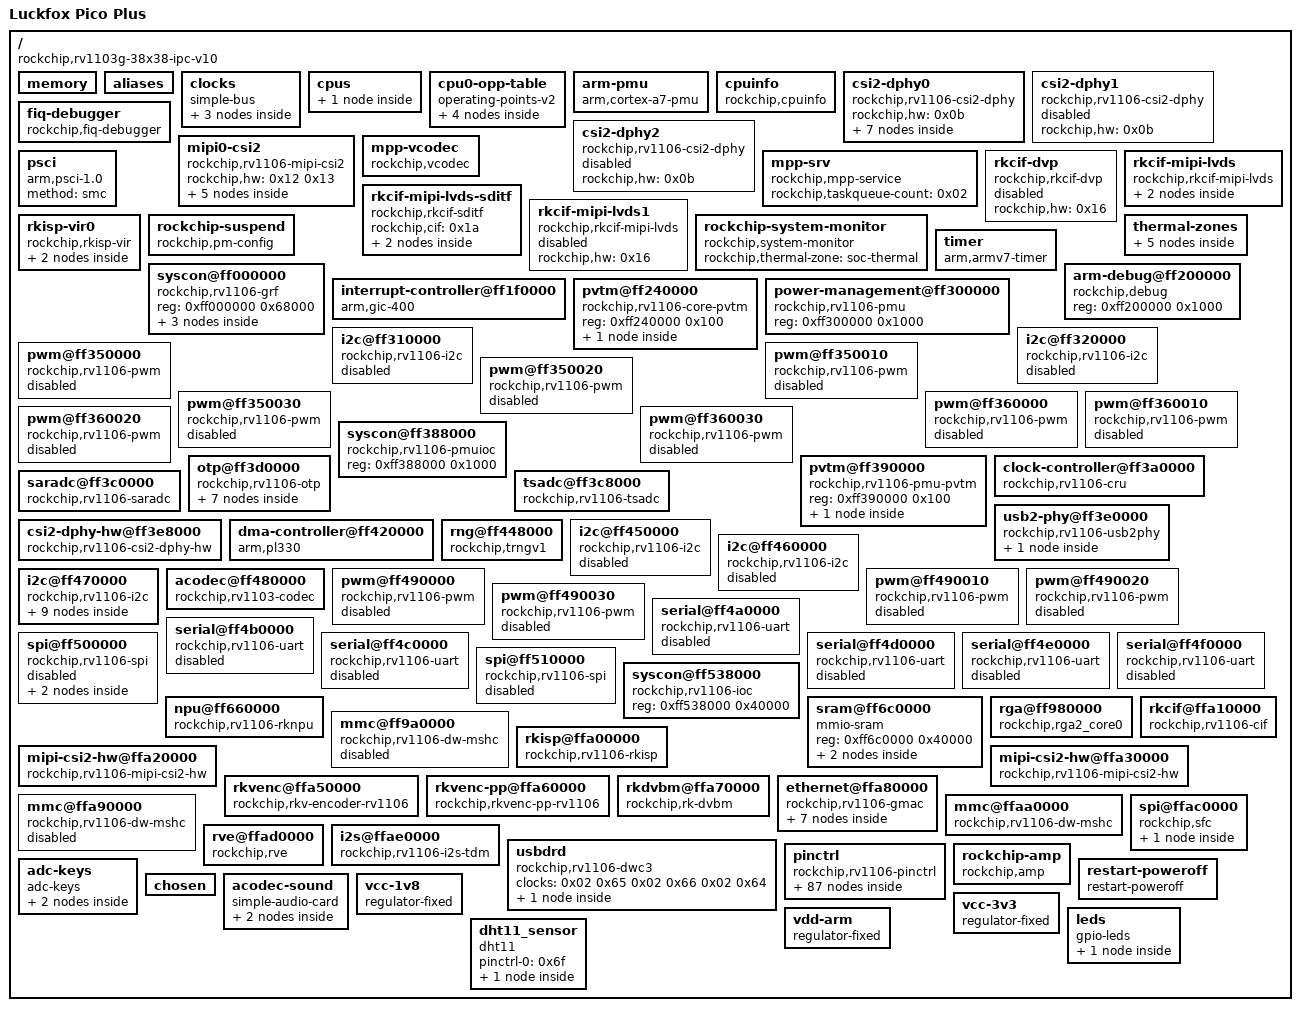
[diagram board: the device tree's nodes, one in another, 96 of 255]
/dts-v1/;

/memreserve/	0x0000000000c00000 0x0000000000009000;
/ {
	serial-number = "6f0e92eba599e63";
	#address-cells = <0x01>;
	#size-cells = <0x01>;
	compatible = "rockchip,rv1103g-38x38-ipc-v10", "rockchip,rv1103";
	interrupt-parent = <0x01>;
	model = "Luckfox Pico Plus";

	memory {
		reg = <0x00 0x4000000 0x00 0x00 0x00 0x00 0x00 0x00 0x00 0x00 0x00 0x00 0x00 0x00 0x00 0x00 0x00 0x00 0x00 0x00 0x00 0x00 0x00 0x00>;
		device_type = "memory";
	};

	aliases {
		csi2dphy0 = "/csi2-dphy0";
		csi2dphy1 = "/csi2-dphy1";
		csi2dphy2 = "/csi2-dphy2";
		ethernet0 = "/ethernet@ffa80000";
		gpio0 = "/pinctrl/gpio@ff380000";
		gpio1 = "/pinctrl/gpio@ff530000";
		gpio3 = "/pinctrl/gpio@ff550000";
		gpio4 = "/pinctrl/gpio@ff560000";
		i2c0 = "/i2c@ff310000";
		i2c1 = "/i2c@ff320000";
		i2c2 = "/i2c@ff450000";
		i2c3 = "/i2c@ff460000";
		i2c4 = "/i2c@ff470000";
		mmc0 = "/mmc@ffa90000";
		mmc1 = "/mmc@ffaa0000";
		mmc2 = "/mmc@ff9a0000";
		pwm0 = "/pwm@ff350000";
		pwm1 = "/pwm@ff350010";
		pwm2 = "/pwm@ff350020";
		pwm3 = "/pwm@ff350030";
		pwm4 = "/pwm@ff360000";
		pwm5 = "/pwm@ff360010";
		pwm6 = "/pwm@ff360020";
		pwm7 = "/pwm@ff360030";
		pwm8 = "/pwm@ff490000";
		pwm9 = "/pwm@ff490010";
		pwm10 = "/pwm@ff490020";
		pwm11 = "/pwm@ff490030";
		rkcif_mipi_lvds0 = "/rkcif-mipi-lvds";
		rkcif_mipi_lvds1 = "/rkcif-mipi-lvds1";
		serial0 = "/serial@ff4a0000";
		serial1 = "/serial@ff4b0000";
		serial2 = "/serial@ff4c0000";
		serial3 = "/serial@ff4d0000";
		serial4 = "/serial@ff4e0000";
		serial5 = "/serial@ff4f0000";
		spi0 = "/spi@ff500000";
		spi1 = "/spi@ff510000";
		spi2 = "/spi@ffac0000";
	};

	clocks {
		compatible = "simple-bus";

		pvtpll-0 {
			compatible = "fixed-clock";
			clock-frequency = <0x18701a80>;
			clock-output-names = "clk_pvtpll_0";
			#clock-cells = <0x00>;
		};

		pvtpll-1 {
			compatible = "fixed-clock";
			clock-frequency = <0x1908b100>;
			clock-output-names = "clk_pvtpll_1";
			#clock-cells = <0x00>;
		};

		oscillator {
			compatible = "fixed-clock";
			clock-frequency = <0x16e3600>;
			clock-output-names = "xin24m";
			#clock-cells = <0x00>;
		};
	};

	cpus {
		#address-cells = <0x01>;
		#size-cells = <0x00>;

		cpu@0 {
			device_type = "cpu";
			compatible = "arm,cortex-a7";
			reg = <0x00>;
			clocks = <0x02 0x05>;
			operating-points-v2 = <0x03>;
			cpu-supply = <0x04>;
			phandle = <0x07>;
		};
	};

	cpu0-opp-table {
		compatible = "operating-points-v2";
		opp-shared;
		nvmem-cells = <0x05>;
		nvmem-cell-names = "leakage";
		rockchip,pvtpll-avg-offset = <0x4001c>;
		rockchip,pvtpll-min-rate = <0x10d880>;
		rockchip,pvtpll-volt-step = <0x30d4>;
		rockchip,grf = <0x06>;
		rockchip,temp-hysteresis = <0x1388>;
		rockchip,low-temp = <0x2710>;
		rockchip,low-temp-min-volt = <0xdbba0>;
		phandle = <0x03>;

		opp-408000000 {
			opp-hz = <0x00 0x18519600>;
			opp-microvolt = <0xcf850 0xcf850 0xf4240>;
			clock-latency-ns = <0x9c40>;
		};

		opp-600000000 {
			opp-hz = <0x00 0x23c34600>;
			opp-microvolt = <0xcf850 0xcf850 0xf4240>;
			clock-latency-ns = <0x9c40>;
		};

		opp-816000000 {
			opp-hz = <0x00 0x30a32c00>;
			opp-microvolt = <0xcf850 0xcf850 0xf4240>;
			clock-latency-ns = <0x9c40>;
			opp-suspend;
		};

		opp-1104000000 {
			opp-hz = <0x00 0x41cdb400>;
			opp-microvolt = <0xcf850 0xcf850 0xf4240>;
			clock-latency-ns = <0x9c40>;
		};
	};

	arm-pmu {
		compatible = "arm,cortex-a7-pmu";
		interrupts = <0x00 0x7e 0x04>;
		interrupt-affinity = <0x07>;
	};

	cpuinfo {
		compatible = "rockchip,cpuinfo";
		nvmem-cells = <0x08 0x09 0x0a>;
		nvmem-cell-names = "id", "cpu-version", "cpu-code";
	};

	csi2-dphy0 {
		compatible = "rockchip,rv1106-csi2-dphy";
		rockchip,hw = <0x0b>;
		status = "okay";

		ports {
			#address-cells = <0x01>;
			#size-cells = <0x00>;

			port@0 {
				reg = <0x00>;
				#address-cells = <0x01>;
				#size-cells = <0x00>;

				endpoint@0 {
					reg = <0x00>;
					remote-endpoint = <0x0c>;
					data-lanes = <0x01 0x02>;
					phandle = <0x33>;
				};

				endpoint@1 {
					reg = <0x01>;
					remote-endpoint = <0x0d>;
					data-lanes = <0x01 0x02>;
					phandle = <0x34>;
				};

				endpoint@2 {
					reg = <0x02>;
					remote-endpoint = <0x0e>;
					data-lanes = <0x01 0x02>;
					phandle = <0x35>;
				};
			};

			port@1 {
				reg = <0x01>;
				#address-cells = <0x01>;
				#size-cells = <0x00>;

				endpoint@0 {
					reg = <0x00>;
					remote-endpoint = <0x0f>;
					phandle = <0x14>;
				};
			};
		};
	};

	csi2-dphy1 {
		compatible = "rockchip,rv1106-csi2-dphy";
		rockchip,hw = <0x0b>;
		status = "disabled";
	};

	csi2-dphy2 {
		compatible = "rockchip,rv1106-csi2-dphy";
		rockchip,hw = <0x0b>;
		status = "disabled";
	};

	fiq-debugger {
		compatible = "rockchip,fiq-debugger";
		rockchip,serial-id = <0x02>;
		rockchip,wake-irq = <0x00>;
		rockchip,irq-mode-enable = <0x01>;
		rockchip,baudrate = <0x1c200>;
		interrupts = <0x00 0x7d 0x04>;
		status = "okay";
	};

	mipi0-csi2 {
		compatible = "rockchip,rv1106-mipi-csi2";
		rockchip,hw = <0x12 0x13>;
		status = "okay";

		ports {
			#address-cells = <0x01>;
			#size-cells = <0x00>;

			port@0 {
				reg = <0x00>;
				#address-cells = <0x01>;
				#size-cells = <0x00>;

				endpoint@1 {
					reg = <0x01>;
					remote-endpoint = <0x14>;
					phandle = <0x0f>;
				};
			};

			port@1 {
				reg = <0x01>;
				#address-cells = <0x01>;
				#size-cells = <0x00>;

				endpoint@0 {
					reg = <0x00>;
					remote-endpoint = <0x15>;
					phandle = <0x19>;
				};
			};
		};
	};

	mpp-srv {
		compatible = "rockchip,mpp-service";
		rockchip,taskqueue-count = <0x02>;
		status = "okay";
		phandle = <0x53>;
	};

	mpp-vcodec {
		compatible = "rockchip,vcodec";
		status = "okay";
	};

	psci {
		compatible = "arm,psci-1.0";
		method = "smc";
	};

	rkcif-dvp {
		compatible = "rockchip,rkcif-dvp";
		rockchip,hw = <0x16>;
		status = "disabled";
		phandle = <0x17>;
	};

	rkcif-mipi-lvds {
		compatible = "rockchip,rkcif-mipi-lvds";
		rockchip,hw = <0x16>;
		status = "okay";
		pinctrl-names = "default";
		pinctrl-0 = <0x18>;
		phandle = <0x1a>;

		port {

			endpoint {
				remote-endpoint = <0x19>;
				phandle = <0x15>;
			};
		};
	};

	rkcif-mipi-lvds-sditf {
		compatible = "rockchip,rkcif-sditf";
		rockchip,cif = <0x1a>;
		status = "okay";

		port {

			endpoint {
				remote-endpoint = <0x1b>;
				phandle = <0x1f>;
			};
		};
	};

	rkcif-mipi-lvds1 {
		compatible = "rockchip,rkcif-mipi-lvds";
		rockchip,hw = <0x16>;
		status = "disabled";
		phandle = <0x1c>;
	};

	rkisp-vir0 {
		compatible = "rockchip,rkisp-vir";
		rockchip,hw = <0x1d>;
		dvbm = <0x1e>;
		status = "okay";

		port@0 {

			endpoint {
				remote-endpoint = <0x1f>;
				phandle = <0x1b>;
			};
		};
	};

	rockchip-suspend {
		compatible = "rockchip,pm-config";
		status = "okay";
		rockchip,sleep-io-config = <0x800 0x10800 0x20800 0x30400 0x40400 0x50000 0x60000>;
	};

	rockchip-system-monitor {
		compatible = "rockchip,system-monitor";
		rockchip,thermal-zone = "soc-thermal";
	};

	thermal-zones {

		soc-thermal {
			polling-delay-passive = <0x14>;
			polling-delay = <0x3e8>;
			sustainable-power = <0x834>;
			thermal-sensors = <0x20 0x00>;

			trips {

				trip-point-0 {
					temperature = <0x124f8>;
					hysteresis = <0x7d0>;
					type = "passive";
				};

				trip-point-1 {
					temperature = <0x14c08>;
					hysteresis = <0x7d0>;
					type = "passive";
				};

				soc-crit {
					temperature = <0x1c138>;
					hysteresis = <0x7d0>;
					type = "critical";
				};
			};
		};
	};

	timer {
		compatible = "arm,armv7-timer";
		interrupts = <0x01 0x0d 0x104 0x01 0x0e 0x104>;
		clock-frequency = <0x16e3600>;
	};

	syscon@ff000000 {
		compatible = "rockchip,rv1106-grf", "syscon", "simple-mfd";
		reg = <0xff000000 0x68000>;
		phandle = <0x06>;

		grf-clock-controller {
			compatible = "rockchip,rv1106-grf-cru";
			#clock-cells = <0x01>;
			phandle = <0x51>;
		};

		reboot-mode {
			compatible = "syscon-reboot-mode";
			offset = <0x20200>;
			mode-bootloader = <0x5242c301>;
			mode-charge = <0x5242c30b>;
			mode-fastboot = <0x5242c309>;
			mode-loader = <0x5242c301>;
			mode-normal = <0x5242c300>;
			mode-recovery = <0x5242c303>;
			mode-ums = <0x5242c30c>;
			mode-panic = <0x5242c307>;
			mode-watchdog = <0x5242c308>;
		};

		rknpor-powergood {
			compatible = "rockchip,rv1106-npor-powergood";
			interrupts = <0x00 0x56 0x04>;
			status = "okay";
		};
	};

	interrupt-controller@ff1f0000 {
		compatible = "arm,gic-400";
		interrupt-controller;
		#interrupt-cells = <0x03>;
		#address-cells = <0x00>;
		reg = <0xff1f1000 0x1000 0xff1f2000 0x2000 0xff1f4000 0x2000 0xff1f6000 0x2000>;
		interrupts = <0x01 0x09 0x104>;
		phandle = <0x01>;
	};

	arm-debug@ff200000 {
		compatible = "rockchip,debug";
		reg = <0xff200000 0x1000>;
	};

	pvtm@ff240000 {
		compatible = "rockchip,rv1106-core-pvtm";
		reg = <0xff240000 0x100>;
		#address-cells = <0x01>;
		#size-cells = <0x00>;

		pvtm@0 {
			reg = <0x00>;
			clocks = <0x02 0x40>;
			clock-names = "clk";
			resets = <0x02 0x6000e 0x02 0x6000f>;
			reset-names = "rst", "rst-p";
		};
	};

	power-management@ff300000 {
		compatible = "rockchip,rv1106-pmu", "syscon";
		reg = <0xff300000 0x1000>;
	};

	i2c@ff310000 {
		compatible = "rockchip,rv1106-i2c", "rockchip,rk3399-i2c";
		reg = <0xff310000 0x1000>;
		interrupts = <0x00 0x12 0x04>;
		#address-cells = <0x01>;
		#size-cells = <0x00>;
		clocks = <0x02 0x2a 0x02 0x29>;
		clock-names = "i2c", "pclk";
		pinctrl-names = "default";
		pinctrl-0 = <0x21>;
		status = "disabled";
		clock-frequency = <0x186a0>;
	};

	i2c@ff320000 {
		compatible = "rockchip,rv1106-i2c", "rockchip,rk3399-i2c";
		reg = <0xff320000 0x1000>;
		interrupts = <0x00 0x13 0x04>;
		#address-cells = <0x01>;
		#size-cells = <0x00>;
		clocks = <0x02 0x78 0x02 0x77>;
		clock-names = "i2c", "pclk";
		pinctrl-names = "default";
		pinctrl-0 = <0x22>;
		status = "disabled";
	};

	pwm@ff350000 {
		compatible = "rockchip,rv1106-pwm", "rockchip,rk3328-pwm";
		reg = <0xff350000 0x10>;
		interrupts = <0x00 0x1f 0x04>;
		#pwm-cells = <0x03>;
		pinctrl-names = "active";
		pinctrl-0 = <0x24 0x25>;
		clocks = <0x02 0x36 0x02 0x35>;
		clock-names = "pwm", "pclk";
		status = "disabled";
	};

	pwm@ff350010 {
		compatible = "rockchip,rv1106-pwm", "rockchip,rk3328-pwm";
		reg = <0xff350010 0x10>;
		interrupts = <0x00 0x1f 0x04>;
		#pwm-cells = <0x03>;
		pinctrl-names = "active";
		pinctrl-0 = <0x26>;
		clocks = <0x02 0x36 0x02 0x35>;
		clock-names = "pwm", "pclk";
		status = "disabled";
	};

	pwm@ff350020 {
		compatible = "rockchip,rv1106-pwm", "rockchip,rk3328-pwm";
		reg = <0xff350020 0x10>;
		interrupts = <0x00 0x1f 0x04>;
		#pwm-cells = <0x03>;
		pinctrl-names = "active";
		pinctrl-0 = <0x27>;
		clocks = <0x02 0x36 0x02 0x35>;
		clock-names = "pwm", "pclk";
		status = "disabled";
	};

	pwm@ff350030 {
		compatible = "rockchip,rv1106-pwm", "rockchip,rk3328-pwm";
		reg = <0xff350030 0x10>;
		interrupts = <0x00 0x1f 0x04 0x00 0x20 0x04>;
		#pwm-cells = <0x03>;
		pinctrl-names = "active";
		pinctrl-0 = <0x28>;
		clocks = <0x02 0x36 0x02 0x35>;
		clock-names = "pwm", "pclk";
		status = "disabled";
	};

	pwm@ff360000 {
		compatible = "rockchip,rv1106-pwm", "rockchip,rk3328-pwm";
		reg = <0xff360000 0x10>;
		interrupts = <0x00 0x21 0x04>;
		#pwm-cells = <0x03>;
		pinctrl-names = "active";
		pinctrl-0 = <0x29>;
		clocks = <0x02 0x44 0x02 0x43>;
		clock-names = "pwm", "pclk";
		status = "disabled";
	};

	pwm@ff360010 {
		compatible = "rockchip,rv1106-pwm", "rockchip,rk3328-pwm";
		reg = <0xff360010 0x10>;
		interrupts = <0x00 0x21 0x04>;
		#pwm-cells = <0x03>;
		pinctrl-names = "active";
		pinctrl-0 = <0x2a>;
		clocks = <0x02 0x44 0x02 0x43>;
		clock-names = "pwm", "pclk";
		status = "disabled";
	};

	pwm@ff360020 {
		compatible = "rockchip,rv1106-pwm", "rockchip,rk3328-pwm";
		reg = <0xff360020 0x10>;
		interrupts = <0x00 0x21 0x04>;
		#pwm-cells = <0x03>;
		pinctrl-names = "active";
		pinctrl-0 = <0x2b>;
		clocks = <0x02 0x44 0x02 0x43>;
		clock-names = "pwm", "pclk";
		status = "disabled";
	};

	pwm@ff360030 {
		compatible = "rockchip,rv1106-pwm", "rockchip,rk3328-pwm";
		reg = <0xff360030 0x10>;
		interrupts = <0x00 0x21 0x04 0x00 0x22 0x04>;
		#pwm-cells = <0x03>;
		pinctrl-names = "active";
		pinctrl-0 = <0x2c>;
		clocks = <0x02 0x44 0x02 0x43>;
		clock-names = "pwm", "pclk";
		status = "disabled";
	};

	syscon@ff388000 {
		compatible = "rockchip,rv1106-pmuioc", "syscon";
		reg = <0xff388000 0x1000>;
		phandle = <0x61>;
	};

	pvtm@ff390000 {
		compatible = "rockchip,rv1106-pmu-pvtm";
		reg = <0xff390000 0x100>;
		#address-cells = <0x01>;
		#size-cells = <0x00>;

		pvtm@0 {
			reg = <0x01>;
			clocks = <0x02 0x7e 0x02 0x7f>;
			clock-names = "clk", "pclk";
			resets = <0x02 0x14 0x02 0x15>;
			reset-names = "rst", "rst-p";
		};
	};

	clock-controller@ff3a0000 {
		compatible = "rockchip,rv1106-cru";
		reg = <0xff3a0000 0x20000>;
		rockchip,grf = <0x06>;
		#clock-cells = <0x01>;
		#reset-cells = <0x01>;
		assigned-clocks = <0x02 0x04 0x02 0x03 0x02 0x05 0x02 0x39 0x02 0x3a 0x02 0x38 0x02 0x3c 0x02 0xcb 0x02 0x82 0x02 0x83 0x02 0x93>;
		assigned-clock-rates = <0x46cf7100 0x3b9aca00 0x41cdb400 0x17d78400 0xbebc200 0x5f5e100 0x11e1a300 0x5f5e100 0x5f5e100 0xbebc200 0xfbc5200>;
		phandle = <0x02>;
	};

	saradc@ff3c0000 {
		compatible = "rockchip,rv1106-saradc";
		reg = <0xff3c0000 0x200>;
		interrupts = <0x00 0x3e 0x04>;
		#io-channel-cells = <0x01>;
		clocks = <0x02 0x4d 0x02 0x4c>;
		clock-names = "saradc", "apb_pclk";
		resets = <0x02 0x48033>;
		reset-names = "saradc-apb";
		status = "okay";
		vref-supply = <0x2d>;
		phandle = <0x6c>;
	};

	tsadc@ff3c8000 {
		compatible = "rockchip,rv1106-tsadc";
		reg = <0xff3c8000 0x1000>;
		rockchip,grf = <0x06>;
		interrupts = <0x00 0x61 0x04>;
		clocks = <0x02 0x113 0x02 0x112 0x02 0x114>;
		clock-names = "tsadc", "apb_pclk", "tsen";
		assigned-clocks = <0x02 0x113 0x02 0x114>;
		assigned-clock-rates = <0xf4240 0xb71b00>;
		resets = <0x02 0x70021 0x02 0x70020>;
		reset-names = "tsadc", "tsadc-apb";
		#thermal-sensor-cells = <0x01>;
		rockchip,hw-tshut-temp = <0x1d4c0>;
		rockchip,hw-tshut-mode = <0x00>;
		rockchip,hw-tshut-polarity = <0x00>;
		status = "okay";
		phandle = <0x20>;
	};

	otp@ff3d0000 {
		compatible = "rockchip,rv1106-otp";
		reg = <0xff3d0000 0x4000>;
		#address-cells = <0x01>;
		#size-cells = <0x01>;
		clocks = <0x02 0x107 0x02 0x106 0x02 0x105 0x02 0x10b 0x02 0x104 0x02 0x10c>;
		clock-names = "usr", "sbpi", "apb", "phy", "arb", "pmc";
		resets = <0x02 0x70026 0x02 0x70025 0x02 0x70023 0x02 0x7002e 0x02 0x7002b 0x02 0x7002f>;
		reset-names = "usr", "sbpi", "apb", "phy", "arb", "pmc";

		cpu-code@2 {
			reg = <0x02 0x02>;
			phandle = <0x0a>;
		};

		cpu-version@8 {
			reg = <0x08 0x01>;
			bits = <0x03 0x03>;
			phandle = <0x09>;
		};

		id@a {
			reg = <0x0a 0x10>;
			phandle = <0x08>;
		};

		cpu-leakage@1a {
			reg = <0x1a 0x01>;
			phandle = <0x05>;
		};

		log-leakage@1b {
			reg = <0x1b 0x01>;
		};

		macphy-bgs@2d {
			reg = <0x2d 0x01>;
			phandle = <0x58>;
		};

		macphy-txlevel@2e {
			reg = <0x2e 0x02>;
			phandle = <0x59>;
		};
	};

	usb2-phy@ff3e0000 {
		compatible = "rockchip,rv1106-usb2phy";
		reg = <0xff3e0000 0x8000>;
		rockchip,usbgrf = <0x06>;
		clocks = <0x02 0x68 0x02 0x67>;
		clock-names = "phyclk", "pclk";
		resets = <0x02 0x48052 0x02 0x48051>;
		reset-names = "u2phy", "u2phy-apb";
		#clock-cells = <0x00>;
		status = "okay";
		phandle = <0x5f>;

		otg-port {
			#phy-cells = <0x00>;
			interrupts = <0x00 0x3a 0x04 0x00 0x3b 0x04 0x00 0x3c 0x04 0x00 0x3d 0x04>;
			interrupt-names = "otg-bvalid", "otg-id", "linestate", "disconnect";
			status = "okay";
			rockchip,vbus-always-on;
			phandle = <0x5e>;
		};
	};

	csi2-dphy-hw@ff3e8000 {
		compatible = "rockchip,rv1106-csi2-dphy-hw";
		reg = <0xff3e8000 0x8000>;
		clocks = <0x02 0xe6>;
		clock-names = "pclk";
		resets = <0x02 0x5001e>;
		reset-names = "srst_p_csiphy";
		rockchip,grf = <0x06>;
		status = "okay";
		phandle = <0x0b>;
	};

	dma-controller@ff420000 {
		compatible = "arm,pl330", "arm,primecell";
		reg = <0xff420000 0x4000>;
		interrupts = <0x00 0x3f 0x04 0x00 0x40 0x04 0x00 0x41 0x04 0x00 0x42 0x04 0x00 0x43 0x04 0x00 0x44 0x04 0x00 0x45 0x04 0x00 0x46 0x04 0x00 0x4f 0x04>;
		#dma-cells = <0x01>;
		clocks = <0x02 0x22>;
		clock-names = "apb_pclk";
		arm,pl330-periph-burst;
		phandle = <0x3f>;
	};

	rng@ff448000 {
		compatible = "rockchip,trngv1";
		reg = <0xff448000 0x200>;
		interrupts = <0x00 0x11 0x04>;
		clocks = <0x02 0x5a>;
		clock-names = "hclk_trng";
		resets = <0x02 0x48039>;
		reset-names = "reset";
		status = "okay";
	};

	i2c@ff450000 {
		compatible = "rockchip,rv1106-i2c", "rockchip,rk3399-i2c";
		reg = <0xff450000 0x1000>;
		interrupts = <0x00 0x14 0x04>;
		#address-cells = <0x01>;
		#size-cells = <0x00>;
		clocks = <0x02 0x2c 0x02 0x2b>;
		clock-names = "i2c", "pclk";
		pinctrl-names = "default";
		pinctrl-0 = <0x2e>;
		status = "disabled";
	};

	i2c@ff460000 {
		compatible = "rockchip,rv1106-i2c", "rockchip,rk3399-i2c";
		reg = <0xff460000 0x1000>;
		interrupts = <0x00 0x15 0x04>;
		#address-cells = <0x01>;
		#size-cells = <0x00>;
		clocks = <0x02 0x2e 0x02 0x2d>;
		clock-names = "i2c", "pclk";
		pinctrl-names = "default";
		pinctrl-0 = <0x2f>;
		status = "disabled";
		clock-frequency = <0x186a0>;
	};

	i2c@ff470000 {
		compatible = "rockchip,rv1106-i2c", "rockchip,rk3399-i2c";
		reg = <0xff470000 0x1000>;
		interrupts = <0x00 0x16 0x04>;
		#address-cells = <0x01>;
		#size-cells = <0x00>;
		clocks = <0x02 0x30 0x02 0x2f>;
		clock-names = "i2c", "pclk";
		pinctrl-names = "default";
		pinctrl-0 = <0x30>;
		status = "okay";
		clock-frequency = <0x61a80>;

		sc3336@30 {
			compatible = "smartsens,sc3336";
			status = "okay";
			reg = <0x30>;
			clocks = <0x02 0xa5>;
			clock-names = "xvclk";
			pwdn-gpios = <0x31 0x15 0x00>;
			pinctrl-names = "default";
			pinctrl-0 = <0x32>;
			rockchip,camera-module-index = <0x00>;
			rockchip,camera-module-facing = "back";
			rockchip,camera-module-name = "CMK-OT2119-PC1";
			rockchip,camera-module-lens-name = "30IRC-F16";

			port {

				endpoint {
					remote-endpoint = <0x33>;
					data-lanes = <0x01 0x02>;
					phandle = <0x0c>;
				};
			};
		};

		sc4336@30 {
			compatible = "smartsens,sc4336";
			status = "okay";
			reg = <0x30>;
			clocks = <0x02 0xa5>;
			clock-names = "xvclk";
			pwdn-gpios = <0x31 0x15 0x00>;
			pinctrl-names = "default";
			pinctrl-0 = <0x32>;
			rockchip,camera-module-index = <0x00>;
			rockchip,camera-module-facing = "back";
			rockchip,camera-module-name = "OT01";
			rockchip,camera-module-lens-name = "40IRC_F16";

			port {

				endpoint {
					remote-endpoint = <0x34>;
					data-lanes = <0x01 0x02>;
					phandle = <0x0d>;
				};
			};
		};

		sc530ai@30 {
			compatible = "smartsens,sc530ai";
			status = "okay";
			reg = <0x30>;
			clocks = <0x02 0xa5>;
			clock-names = "xvclk";
			pwdn-gpios = <0x31 0x15 0x00>;
			pinctrl-names = "default";
			pinctrl-0 = <0x32>;
			rockchip,camera-module-index = <0x00>;
			rockchip,camera-module-facing = "back";
			rockchip,camera-module-name = "CMK-OT2115-PC1";
			rockchip,camera-module-lens-name = "30IRC-F16";

			port {

				endpoint {
					remote-endpoint = <0x35>;
					data-lanes = <0x01 0x02>;
					phandle = <0x0e>;
				};
			};
		};
	};

	acodec@ff480000 {
		compatible = "rockchip,rv1103-codec";
		reg = <0xff480000 0x1000>;
		rockchip,grf = <0x06>;
		clocks = <0x02 0x18 0x02 0x19 0x02 0x9f>;
		clock-names = "pclk_acodec", "mclk_acodec", "mclk_cpu";
		resets = <0x02 0x48063>;
		reset-names = "acodec-reset";
		acodec,micbias;
		init-mic-gain = <0x22>;
		status = "okay";
		#sound-dai-cells = <0x00>;
		pa-ctl-gpios = <0x36 0x01 0x00>;
		phandle = <0x6e>;
	};

	pwm@ff490000 {
		compatible = "rockchip,rv1106-pwm", "rockchip,rk3328-pwm";
		reg = <0xff490000 0x10>;
		interrupts = <0x00 0x23 0x04>;
		#pwm-cells = <0x03>;
		pinctrl-names = "active";
		pinctrl-0 = <0x37 0x38>;
		clocks = <0x02 0x47 0x02 0x46>;
		clock-names = "pwm", "pclk";
		status = "disabled";
	};

	pwm@ff490010 {
		compatible = "rockchip,rv1106-pwm", "rockchip,rk3328-pwm";
		reg = <0xff490010 0x10>;
		interrupts = <0x00 0x23 0x04>;
		#pwm-cells = <0x03>;
		pinctrl-names = "active";
		pinctrl-0 = <0x39 0x3a>;
		clocks = <0x02 0x47 0x02 0x46>;
		clock-names = "pwm", "pclk";
		status = "disabled";
	};

	pwm@ff490020 {
		compatible = "rockchip,rv1106-pwm", "rockchip,rk3328-pwm";
		reg = <0xff490020 0x10>;
		interrupts = <0x00 0x23 0x04>;
		#pwm-cells = <0x03>;
		pinctrl-names = "active";
		pinctrl-0 = <0x3b 0x3c>;
		clocks = <0x02 0x47 0x02 0x46>;
		clock-names = "pwm", "pclk";
		status = "disabled";
	};

	pwm@ff490030 {
		compatible = "rockchip,rv1106-pwm", "rockchip,rk3328-pwm";
		reg = <0xff490030 0x10>;
		interrupts = <0x00 0x23 0x04 0x00 0x24 0x04>;
		#pwm-cells = <0x03>;
		pinctrl-names = "active";
		pinctrl-0 = <0x3d 0x3e>;
		clocks = <0x02 0x47 0x02 0x46>;
		clock-names = "pwm", "pclk";
		status = "disabled";
	};

	serial@ff4a0000 {
		compatible = "rockchip,rv1106-uart", "snps,dw-apb-uart";
		reg = <0xff4a0000 0x100>;
		interrupts = <0x00 0x19 0x04>;
		reg-shift = <0x02>;
		reg-io-width = <0x04>;
		dmas = <0x3f 0x07 0x3f 0x06>;
		clock-frequency = <0x16e3600>;
		clocks = <0x02 0xac 0x02 0x3f>;
		clock-names = "baudclk", "apb_pclk";
		pinctrl-names = "default";
		pinctrl-0 = <0x40>;
		status = "disabled";
	};

	serial@ff4b0000 {
		compatible = "rockchip,rv1106-uart", "snps,dw-apb-uart";
		reg = <0xff4b0000 0x100>;
		interrupts = <0x00 0x1a 0x04>;
		reg-shift = <0x02>;
		reg-io-width = <0x04>;
		dmas = <0x3f 0x09 0x3f 0x08>;
		clock-frequency = <0x16e3600>;
		clocks = <0x02 0xb0 0x02 0x41>;
		clock-names = "baudclk", "apb_pclk";
		pinctrl-names = "default";
		pinctrl-0 = <0x41 0x42 0x43>;
		status = "disabled";
	};

	serial@ff4c0000 {
		compatible = "rockchip,rv1106-uart", "snps,dw-apb-uart";
		reg = <0xff4c0000 0x100>;
		interrupts = <0x00 0x1b 0x04>;
		reg-shift = <0x02>;
		reg-io-width = <0x04>;
		dmas = <0x3f 0x0b 0x3f 0x0a>;
		clock-frequency = <0x16e3600>;
		clocks = <0x02 0xb4 0x02 0x5c>;
		clock-names = "baudclk", "apb_pclk";
		pinctrl-names = "default";
		pinctrl-0 = <0x44>;
		status = "disabled";
	};

	serial@ff4d0000 {
		compatible = "rockchip,rv1106-uart", "snps,dw-apb-uart";
		reg = <0xff4d0000 0x100>;
		interrupts = <0x00 0x1c 0x04>;
		reg-shift = <0x02>;
		reg-io-width = <0x04>;
		dmas = <0x3f 0x0d 0x3f 0x0c>;
		clock-frequency = <0x16e3600>;
		clocks = <0x02 0xb8 0x02 0x5e>;
		clock-names = "baudclk", "apb_pclk";
		pinctrl-names = "default";
		pinctrl-0 = <0x45>;
		status = "disabled";
	};

	serial@ff4e0000 {
		compatible = "rockchip,rv1106-uart", "snps,dw-apb-uart";
		reg = <0xff4e0000 0x100>;
		interrupts = <0x00 0x1d 0x04>;
		reg-shift = <0x02>;
		reg-io-width = <0x04>;
		dmas = <0x3f 0x0f 0x3f 0x0e>;
		clock-frequency = <0x16e3600>;
		clocks = <0x02 0xbc 0x02 0x60>;
		clock-names = "baudclk", "apb_pclk";
		pinctrl-names = "default";
		pinctrl-0 = <0x46>;
		status = "disabled";
	};

	serial@ff4f0000 {
		compatible = "rockchip,rv1106-uart", "snps,dw-apb-uart";
		reg = <0xff4f0000 0x100>;
		interrupts = <0x00 0x1e 0x04>;
		reg-shift = <0x02>;
		reg-io-width = <0x04>;
		dmas = <0x3f 0x11 0x3f 0x10>;
		clock-frequency = <0x16e3600>;
		clocks = <0x02 0xc0 0x02 0x62>;
		clock-names = "baudclk", "apb_pclk";
		pinctrl-names = "default";
		pinctrl-0 = <0x47>;
		status = "disabled";
	};

	spi@ff500000 {
		compatible = "rockchip,rv1106-spi", "rockchip,rk3066-spi";
		reg = <0xff500000 0x1000>;
		interrupts = <0x00 0x17 0x04>;
		#address-cells = <0x01>;
		#size-cells = <0x00>;
		clocks = <0x02 0xcd 0x02 0xcc 0x02 0xce>;
		clock-names = "spiclk", "apb_pclk", "sclk_in";
		dmas = <0x3f 0x01 0x3f 0x00>;
		dma-names = "tx", "rx";
		pinctrl-names = "default";
		pinctrl-0 = <0x48 0x49 0x4a 0x4b>;
		status = "disabled";

		spidev@0 {
			compatible = "rockchip,spidev";
			spi-max-frequency = <0x2faf080>;
			reg = <0x00>;
		};

		fbtft@0 {
			compatible = "sitronix,st7789v";
			reg = <0x00>;
			spi-max-frequency = <0x2faf080>;
			fps = <0x1e>;
			buswidth = <0x08>;
			debug = <0x07>;
			led-gpios = <0x4c 0x04 0x00>;
			dc-gpios = <0x36 0x02 0x00>;
			reset-gpios = <0x36 0x13 0x01>;
		};
	};

	spi@ff510000 {
		compatible = "rockchip,rv1106-spi", "rockchip,rk3066-spi";
		reg = <0xff510000 0x1000>;
		interrupts = <0x00 0x18 0x04>;
		#address-cells = <0x01>;
		#size-cells = <0x00>;
		clocks = <0x02 0x4f 0x02 0x4e>;
		clock-names = "spiclk", "apb_pclk";
		assigned-clocks = <0x02 0x4f>;
		assigned-clock-rates = <0xbebc200>;
		dmas = <0x3f 0x03 0x3f 0x02>;
		dma-names = "tx", "rx";
		pinctrl-names = "default";
		pinctrl-0 = <0x4d 0x4e 0x4f>;
		status = "disabled";
	};

	syscon@ff538000 {
		compatible = "rockchip,rv1106-ioc", "syscon";
		reg = <0xff538000 0x40000>;
		phandle = <0x60>;
	};

	npu@ff660000 {
		compatible = "rockchip,rv1106-rknpu";
		reg = <0xff660000 0x10000>;
		interrupts = <0x00 0x6d 0x04>;
		clocks = <0x02 0x17 0x02 0x16>;
		clock-names = "aclk", "hclk";
		assigned-clocks = <0x02 0x17>;
		assigned-clock-rates = <0x1908b100>;
		resets = <0x02 0x5800a 0x02 0x58009>;
		reset-names = "srst_a", "srst_h";
		status = "okay";
	};

	sram@ff6c0000 {
		compatible = "mmio-sram";
		reg = <0xff6c0000 0x40000>;
		#address-cells = <0x01>;
		#size-cells = <0x01>;
		ranges = <0x00 0xff6c0000 0x40000>;

		rkisp-sram@0 {
			reg = <0x00 0x3e000>;
			phandle = <0x52>;
		};

		hpmcu-sram@3e000 {
			reg = <0x3e000 0x2000>;
		};
	};

	rga@ff980000 {
		compatible = "rockchip,rga2_core0";
		reg = <0xff980000 0x1000>;
		interrupts = <0x00 0x57 0x04>;
		clocks = <0x02 0x10e 0x02 0x10d 0x02 0x10f>;
		clock-names = "aclk_rga2", "hclk_rga2", "clk_rga2";
		status = "okay";
	};

	mmc@ff9a0000 {
		compatible = "rockchip,rv1106-dw-mshc", "rockchip,rk3288-dw-mshc";
		reg = <0xff9a0000 0x4000>;
		interrupts = <0x00 0x31 0x04>;
		clocks = <0x02 0x111 0x02 0x110 0x51 0x05 0x51 0x06>;
		clock-names = "biu", "ciu", "ciu-drive", "ciu-sample";
		fifo-depth = <0x100>;
		max-frequency = <0xbebc200>;
		status = "disabled";
	};

	rkisp@ffa00000 {
		compatible = "rockchip,rv1106-rkisp";
		reg = <0xffa00000 0x7f00>;
		interrupts = <0x00 0x69 0x04 0x00 0x68 0x04 0x00 0x67 0x04>;
		interrupt-names = "isp_irq", "mi_irq", "mipi_irq";
		clocks = <0x02 0xe4 0x02 0xe3 0x02 0xe5 0x02 0xf8>;
		clock-names = "aclk_isp", "hclk_isp", "clk_isp_core", "clk_isp_core_vicap";
		rockchip,sram = <0x52>;
		status = "okay";
		phandle = <0x1d>;
	};

	rkcif@ffa10000 {
		compatible = "rockchip,rv1106-cif";
		reg = <0xffa10000 0x10000>;
		reg-names = "cif_regs";
		interrupts = <0x00 0x6a 0x04>;
		interrupt-names = "cif-intr";
		clocks = <0x02 0xf2 0x02 0xf3 0x02 0xf0 0x02 0xf1 0x02 0xf4 0x02 0xf5 0x02 0xf6 0x02 0xf7 0x02 0xf8 0x02 0xc4 0x02 0xc8 0x02 0xdc>;
		clock-names = "aclk_cif", "hclk_cif", "dclk_cif", "pclk_cif", "i0clk_cif", "i1clk_cif", "rx0clk_cif", "rx1clk_cif", "isp0clk_cif", "sclk_m0_cif", "sclk_m1_cif", "pclk_vepu_cif";
		resets = <0x02 0x5000c 0x02 0x5000d 0x02 0x5000a 0x02 0x5000b 0x02 0x5000e 0x02 0x5000f 0x02 0x50010 0x02 0x50011 0x02 0x50012 0x02 0x6800e>;
		reset-names = "rst_cif_a", "rst_cif_h", "rst_cif_d", "rst_cif_p", "rst_cif_i0", "rst_cif_i1", "rst_cif_rx0", "rst_cif_rx1", "rst_cif_isp0", "rst_cif_pclk_vepu";
		rockchip,grf = <0x06>;
		status = "okay";
		phandle = <0x16>;
	};

	mipi-csi2-hw@ffa20000 {
		compatible = "rockchip,rv1106-mipi-csi2-hw";
		reg = <0xffa20000 0x10000>;
		reg-names = "csihost_regs";
		interrupts = <0x00 0x63 0x04 0x00 0x64 0x04>;
		interrupt-names = "csi-intr1", "csi-intr2";
		clocks = <0x02 0xdd 0x02 0xde>;
		clock-names = "pclk_csi2host", "clk_rxbyte_hs";
		resets = <0x02 0x50014>;
		reset-names = "srst_csihost_p";
		status = "okay";
		phandle = <0x12>;
	};

	mipi-csi2-hw@ffa30000 {
		compatible = "rockchip,rv1106-mipi-csi2-hw";
		reg = <0xffa30000 0x10000>;
		reg-names = "csihost_regs";
		interrupts = <0x00 0x65 0x04 0x00 0x66 0x04>;
		interrupt-names = "csi-intr1", "csi-intr2";
		clocks = <0x02 0xdf 0x02 0xe0>;
		clock-names = "pclk_csi2host", "clk_rxbyte_hs";
		resets = <0x02 0x50016>;
		reset-names = "srst_csihost_p";
		status = "okay";
		phandle = <0x13>;
	};

	rkvenc@ffa50000 {
		compatible = "rockchip,rkv-encoder-rv1106";
		reg = <0xffa50000 0x6000>;
		interrupts = <0x00 0x6b 0x04>;
		interrupt-names = "irq_rkvenc";
		clocks = <0x02 0xd1 0x02 0xd0 0x02 0xd2>;
		clock-names = "aclk_vcodec", "hclk_vcodec", "clk_core";
		rockchip,normal-rates = <0x11e1a300 0x00 0x18701a80>;
		assigned-clocks = <0x02 0xd1 0x02 0xd2>;
		assigned-clock-rates = <0x11e1a300 0x17d78400>;
		resets = <0x02 0x68009 0x02 0x68008 0x02 0x6800a>;
		reset-names = "video_a", "video_h", "video_core";
		rockchip,srv = <0x53>;
		rockchip,taskqueue-node = <0x00>;
		dvbm = <0x1e>;
		status = "okay";
	};

	rkvenc-pp@ffa60000 {
		compatible = "rockchip,rkvenc-pp-rv1106";
		reg = <0xffa60000 0x900>;
		interrupts = <0x00 0x6c 0x04>;
		interrupt-names = "irq_rkvenc_pp";
		clocks = <0x02 0xd7 0x02 0xd6>;
		clock-names = "aclk_vepu_pp", "hclk_vepu_pp";
		assigned-clocks = <0x02 0xd7 0x02 0xd6>;
		resets = <0x02 0x6800c 0x02 0x6800b>;
		rockchip,srv = <0x53>;
		rockchip,taskqueue-node = <0x01>;
		status = "okay";
	};

	rkdvbm@ffa70000 {
		compatible = "rockchip,rk-dvbm";
		reg = <0xffa70000 0x90>;
		interrupts = <0x00 0x74 0x04>;
		interrupt-names = "irq_rkdvbm";
		clocks = <0x02 0xd3>;
		clock-names = "clk_core";
		assigned-clocks = <0x02 0xd3>;
		assigned-clock-rates = <0xbebc200>;
		resets = <0x02 0x6800d>;
		reset-names = "dvbm_rst";
		status = "okay";
		phandle = <0x1e>;
	};

	ethernet@ffa80000 {
		local-mac-address = [3e ee ed 81 3c b0];
		compatible = "rockchip,rv1106-gmac", "snps,dwmac-4.20a";
		reg = <0xffa80000 0x10000>;
		interrupts = <0x00 0x5d 0x04 0x00 0x60 0x04>;
		interrupt-names = "macirq", "eth_wake_irq";
		rockchip,grf = <0x06>;
		clocks = <0x02 0xfe 0x02 0xff 0x02 0xfb 0x02 0xfc>;
		clock-names = "stmmaceth", "clk_mac_ref", "aclk_mac", "pclk_mac";
		resets = <0x02 0x70018>;
		reset-names = "stmmaceth";
		snps,mixed-burst;
		snps,tso;
		tx-dma-size = <0x100>;
		rx-dma-size = <0x80>;
		snps,axi-config = <0x54>;
		snps,mtl-rx-config = <0x55>;
		snps,mtl-tx-config = <0x56>;
		phy-mode = "rmii";
		clock_in_out = "input";
		phy-handle = <0x57>;
		snps,flow-ctrl = <0x00>;
		nvmem-cells = <0x58>;
		nvmem-cell-names = "bgs";
		status = "okay";

		mdio {
			compatible = "snps,dwmac-mdio";
			#address-cells = <0x01>;
			#size-cells = <0x00>;

			ethernet-phy@2 {
				compatible = "ethernet-phy-id0044.1400", "ethernet-phy-ieee802.3-c22";
				reg = <0x02>;
				clocks = <0x02 0x103>;
				resets = <0x02 0x7002d>;
				phy-is-integrated;
				nvmem-cells = <0x59>;
				nvmem-cell-names = "txlevel";
				bgs,increment = <0x00>;
				rockchip,thermal-zone = "soc-thermal";
				phandle = <0x57>;
			};
		};

		stmmac-axi-config {
			snps,wr_osr_lmt = <0x04>;
			snps,rd_osr_lmt = <0x08>;
			snps,blen = <0x00 0x00 0x00 0x00 0x10 0x08 0x04>;
			phandle = <0x54>;
		};

		rx-queues-config {
			snps,rx-queues-to-use = <0x01>;
			phandle = <0x55>;

			queue0 {
				status = "okay";
			};
		};

		tx-queues-config {
			snps,tx-queues-to-use = <0x01>;
			phandle = <0x56>;

			queue0 {
				status = "okay";
			};
		};
	};

	mmc@ffa90000 {
		compatible = "rockchip,rv1106-dw-mshc", "rockchip,rk3288-dw-mshc";
		reg = <0xffa90000 0x4000>;
		interrupts = <0x00 0x30 0x04>;
		clocks = <0x02 0x26 0x02 0x25 0x51 0x01 0x51 0x02>;
		clock-names = "biu", "ciu", "ciu-drive", "ciu-sample";
		fifo-depth = <0x100>;
		max-frequency = <0xbebc200>;
		rockchip,use-v2-tuning;
		status = "disabled";
	};

	mmc@ffaa0000 {
		compatible = "rockchip,rv1106-dw-mshc", "rockchip,rk3288-dw-mshc";
		reg = <0xffaa0000 0x4000>;
		interrupts = <0x00 0x34 0x04>;
		clocks = <0x02 0xe8 0x02 0xe7 0x51 0x03 0x51 0x04>;
		clock-names = "biu", "ciu", "ciu-drive", "ciu-sample";
		fifo-depth = <0x100>;
		max-frequency = <0x2faf080>;
		status = "okay";
		no-mmc;
		bus-width = <0x04>;
		cap-mmc-highspeed;
		cap-sd-highspeed;
		disable-wp;
		cap-sdio-irq;
		non-removable;
		no-1-8-v;
		supports-sdio;
		pinctrl-names = "default";
		pinctrl-0 = <0x5a 0x5b 0x5c 0x5d>;
	};

	spi@ffac0000 {
		compatible = "rockchip,sfc";
		reg = <0xffac0000 0x4000>;
		interrupts = <0x00 0x35 0x04>;
		clocks = <0x02 0x3e 0x02 0x3d>;
		clock-names = "clk_sfc", "hclk_sfc";
		#address-cells = <0x01>;
		#size-cells = <0x00>;
		status = "okay";

		flash@0 {
			compatible = "spi-nand";
			reg = <0x00>;
			spi-max-frequency = <0x47868c0>;
			spi-rx-bus-width = <0x04>;
			spi-tx-bus-width = <0x01>;
		};
	};

	rve@ffad0000 {
		compatible = "rockchip,rve";
		reg = <0xffad0000 0x1000>;
		interrupts = <0x00 0x6f 0x04>;
		clocks = <0x02 0x34 0x02 0x33>;
		clock-names = "aclk_rve", "hclk_rve";
		status = "okay";
	};

	i2s@ffae0000 {
		compatible = "rockchip,rv1106-i2s-tdm";
		reg = <0xffae0000 0x1000>;
		interrupts = <0x00 0x50 0x04>;
		clocks = <0x02 0x9f 0x02 0x9e 0x02 0x31>;
		clock-names = "mclk_tx", "mclk_rx", "hclk";
		dmas = <0x3f 0x16 0x3f 0x15>;
		dma-names = "tx", "rx";
		resets = <0x02 0x4805f 0x02 0x48066>;
		reset-names = "tx-m", "rx-m";
		rockchip,clk-trcm = <0x01>;
		#sound-dai-cells = <0x00>;
		status = "okay";
		phandle = <0x6d>;
	};

	usbdrd {
		compatible = "rockchip,rv1106-dwc3", "rockchip,rk3399-dwc3";
		clocks = <0x02 0x65 0x02 0x66 0x02 0x64>;
		clock-names = "ref", "utmi", "bus";
		#address-cells = <0x01>;
		#size-cells = <0x01>;
		ranges;
		status = "okay";

		usb@ffb00000 {
			compatible = "snps,dwc3";
			reg = <0xffb00000 0x100000>;
			interrupts = <0x00 0x36 0x04>;
			resets = <0x02 0x48047>;
			reset-names = "usb3-otg";
			dr_mode = "peripheral";
			maximum-speed = "high-speed";
			phys = <0x5e>;
			phy-names = "usb2-phy";
			phy_type = "utmi_wide";
			snps,dis_enblslpm_quirk;
			snps,dis-u2-freeclk-exists-quirk;
			snps,dis_u2_susphy_quirk;
			snps,dis-del-phy-power-chg-quirk;
			snps,dis-tx-ipgap-linecheck-quirk;
			snps,usb2-gadget-lpm-disable;
			snps,usb2-lpm-disable;
			snps,parkmode-disable-hs-quirk;
			status = "okay";
			extcon = <0x5f>;
		};
	};

	pinctrl {
		compatible = "rockchip,rv1106-pinctrl";
		rockchip,grf = <0x60>;
		rockchip,pmu = <0x61>;
		#address-cells = <0x01>;
		#size-cells = <0x01>;
		ranges;
		phandle = <0x62>;

		gpio@ff380000 {
			compatible = "rockchip,gpio-bank";
			reg = <0xff380000 0x100>;
			interrupts = <0x00 0x05 0x04>;
			clocks = <0x02 0x70 0x02 0x71>;
			gpio-controller;
			#gpio-cells = <0x02>;
			gpio-ranges = <0x62 0x00 0x00 0x20>;
			interrupt-controller;
			#interrupt-cells = <0x02>;
			phandle = <0x4c>;
		};

		gpio@ff530000 {
			compatible = "rockchip,gpio-bank";
			reg = <0xff530000 0x100>;
			interrupts = <0x00 0x07 0x04>;
			clocks = <0x02 0xd4 0x02 0xd5>;
			gpio-controller;
			#gpio-cells = <0x02>;
			gpio-ranges = <0x62 0x00 0x20 0x20>;
			interrupt-controller;
			#interrupt-cells = <0x02>;
			phandle = <0x36>;
		};

		gpio@ff550000 {
			compatible = "rockchip,gpio-bank";
			reg = <0xff550000 0x100>;
			interrupts = <0x00 0x0b 0x04>;
			clocks = <0x02 0xe1 0x02 0xe2>;
			gpio-controller;
			#gpio-cells = <0x02>;
			gpio-ranges = <0x62 0x00 0x60 0x20>;
			interrupt-controller;
			#interrupt-cells = <0x02>;
			phandle = <0x31>;
		};

		gpio@ff560000 {
			compatible = "rockchip,gpio-bank";
			reg = <0xff560000 0x100>;
			interrupts = <0x00 0x0d 0x04>;
			clocks = <0x02 0x27 0x02 0x28>;
			gpio-controller;
			#gpio-cells = <0x02>;
			gpio-ranges = <0x62 0x00 0x80 0x20>;
			interrupt-controller;
			#interrupt-cells = <0x02>;
		};

		pcfg-pull-up {
			bias-pull-up;
			phandle = <0x65>;
		};

		pcfg-pull-down {
			bias-pull-down;
			phandle = <0x6b>;
		};

		pcfg-pull-none {
			bias-disable;
			phandle = <0x63>;
		};

		pcfg-pull-none-drv-level-1 {
			bias-disable;
			drive-strength = <0x01>;
			phandle = <0x6a>;
		};

		pcfg-pull-none-drv-level-2 {
			bias-disable;
			drive-strength = <0x02>;
			phandle = <0x69>;
		};

		pcfg-pull-none-drv-level-3 {
			bias-disable;
			drive-strength = <0x03>;
			phandle = <0x68>;
		};

		pcfg-pull-none-drv-level-4 {
			bias-disable;
			drive-strength = <0x04>;
			phandle = <0x67>;
		};

		pcfg-pull-up-drv-level-2 {
			bias-pull-up;
			drive-strength = <0x02>;
			phandle = <0x64>;
		};

		pcfg-pull-none-smt {
			bias-disable;
			input-schmitt-enable;
			phandle = <0x66>;
		};

		dsmaudio {

			dsmaudio-pins {
				rockchip,pins = <0x01 0x1b 0x07 0x63 0x01 0x1a 0x07 0x63>;
				phandle = <0x23>;
			};
		};

		i2c0 {

			i2c0m2-xfer {
				rockchip,pins = <0x03 0x04 0x03 0x66 0x03 0x05 0x03 0x66>;
				phandle = <0x21>;
			};
		};

		i2c1 {

			i2c1m0-xfer {
				rockchip,pins = <0x00 0x05 0x01 0x66 0x00 0x06 0x01 0x66>;
				phandle = <0x22>;
			};
		};

		i2c2 {

			i2c2m0-xfer {
				rockchip,pins = <0x01 0x00 0x02 0x66 0x01 0x01 0x02 0x66>;
				phandle = <0x2e>;
			};
		};

		i2c3 {

			i2c3m1-xfer {
				rockchip,pins = <0x01 0x1b 0x03 0x66 0x01 0x1a 0x03 0x66>;
				phandle = <0x2f>;
			};
		};

		i2c4 {

			i2c4m2-xfer {
				rockchip,pins = <0x03 0x17 0x03 0x66 0x03 0x18 0x03 0x66>;
				phandle = <0x30>;
			};
		};

		mipi {

			mipi-pins {
				rockchip,pins = <0x03 0x10 0x02 0x63 0x03 0x11 0x02 0x63 0x03 0x0a 0x02 0x63 0x03 0x0b 0x02 0x63 0x03 0x12 0x02 0x63 0x03 0x13 0x02 0x63 0x03 0x0e 0x02 0x63 0x03 0x0f 0x02 0x63 0x03 0x0c 0x02 0x63 0x03 0x0d 0x02 0x63 0x03 0x08 0x02 0x63 0x03 0x09 0x02 0x63>;
				phandle = <0x18>;
			};

			mipi-refclk-out0 {
				rockchip,pins = <0x03 0x14 0x02 0x63>;
				phandle = <0x32>;
			};
		};

		pwm0 {

			pwm0m0-pins {
				rockchip,pins = <0x01 0x02 0x01 0x63>;
				phandle = <0x24>;
			};

			pwm0m1-pins {
				rockchip,pins = <0x01 0x1a 0x06 0x63>;
				phandle = <0x25>;
			};
		};

		pwm1 {

			pwm1m0-pins {
				rockchip,pins = <0x00 0x04 0x02 0x63>;
				phandle = <0x26>;
			};
		};

		pwm2 {

			pwm2m2-pins {
				rockchip,pins = <0x01 0x10 0x03 0x63>;
				phandle = <0x27>;
			};
		};

		pwm3 {

			pwm3m2-pins {
				rockchip,pins = <0x01 0x18 0x03 0x63>;
				phandle = <0x28>;
			};
		};

		pwm4 {

			pwm4m2-pins {
				rockchip,pins = <0x01 0x11 0x03 0x63>;
				phandle = <0x29>;
			};
		};

		pwm5 {

			pwm5m2-pins {
				rockchip,pins = <0x01 0x12 0x03 0x63>;
				phandle = <0x2a>;
			};
		};

		pwm6 {

			pwm6m2-pins {
				rockchip,pins = <0x01 0x13 0x03 0x63>;
				phandle = <0x2b>;
			};
		};

		pwm7 {

			pwm7m0-pins {
				rockchip,pins = <0x01 0x00 0x03 0x63>;
				phandle = <0x2c>;
			};
		};

		pwm8 {

			pwm8m0-pins {
				rockchip,pins = <0x03 0x03 0x04 0x63>;
				phandle = <0x37>;
			};

			pwm8m1-pins {
				rockchip,pins = <0x01 0x14 0x03 0x63>;
				phandle = <0x38>;
			};
		};

		pwm9 {

			pwm9m0-pins {
				rockchip,pins = <0x03 0x02 0x04 0x63>;
				phandle = <0x39>;
			};

			pwm9m1-pins {
				rockchip,pins = <0x01 0x15 0x03 0x63>;
				phandle = <0x3a>;
			};
		};

		pwm10 {

			pwm10m0-pins {
				rockchip,pins = <0x03 0x04 0x05 0x63>;
				phandle = <0x3b>;
			};

			pwm10m1-pins {
				rockchip,pins = <0x01 0x16 0x03 0x63>;
				phandle = <0x3c>;
			};
		};

		pwm11 {

			pwm11m0-pins {
				rockchip,pins = <0x03 0x05 0x05 0x63>;
				phandle = <0x3d>;
			};

			pwm11m1-pins {
				rockchip,pins = <0x01 0x17 0x03 0x63>;
				phandle = <0x3e>;
			};
		};

		sdmmc0 {

			sdmmc0-bus4 {
				rockchip,pins = <0x03 0x03 0x01 0x64 0x03 0x02 0x01 0x64 0x03 0x07 0x01 0x64 0x03 0x06 0x01 0x64>;
				phandle = <0x5d>;
			};

			sdmmc0-clk {
				rockchip,pins = <0x03 0x04 0x01 0x64>;
				phandle = <0x5a>;
			};

			sdmmc0-cmd {
				rockchip,pins = <0x03 0x05 0x01 0x64>;
				phandle = <0x5b>;
			};

			sdmmc0-det {
				rockchip,pins = <0x03 0x01 0x01 0x65>;
				phandle = <0x5c>;
			};
		};

		spi0 {

			spi0m0-cs0 {
				rockchip,pins = <0x01 0x10 0x04 0x63>;
				phandle = <0x4b>;
			};

			spi0m0-clk {
				rockchip,pins = <0x01 0x11 0x04 0x63>;
				phandle = <0x48>;
			};

			spi0m0-mosi {
				rockchip,pins = <0x01 0x12 0x06 0x63>;
				phandle = <0x4a>;
			};

			spi0m0-miso {
				rockchip,pins = <0x01 0x13 0x06 0x63>;
				phandle = <0x49>;
			};
		};

		spi1 {

			spi1m0-pins {
				rockchip,pins = <0x04 0x07 0x02 0x63 0x04 0x00 0x02 0x63 0x04 0x01 0x02 0x63>;
				phandle = <0x4f>;
			};

			spi1m0-cs0 {
				rockchip,pins = <0x04 0x05 0x02 0x63>;
				phandle = <0x4d>;
			};

			spi1m0-cs1 {
				rockchip,pins = <0x01 0x09 0x03 0x63>;
				phandle = <0x4e>;
			};
		};

		uart0 {

			uart0m0-xfer {
				rockchip,pins = <0x00 0x00 0x01 0x65 0x00 0x01 0x01 0x65>;
				phandle = <0x40>;
			};
		};

		uart1 {

			uart1m0-xfer {
				rockchip,pins = <0x01 0x04 0x01 0x65 0x01 0x03 0x01 0x65>;
				phandle = <0x41>;
			};

			uart1m0-ctsn {
				rockchip,pins = <0x00 0x06 0x02 0x63>;
				phandle = <0x42>;
			};

			uart1m0-rtsn {
				rockchip,pins = <0x00 0x05 0x02 0x63>;
				phandle = <0x43>;
			};
		};

		uart2 {

			uart2m1-xfer {
				rockchip,pins = <0x01 0x0b 0x02 0x65 0x01 0x0a 0x02 0x65>;
				phandle = <0x44>;
			};
		};

		uart3 {

			uart3m1-xfer {
				rockchip,pins = <0x01 0x19 0x05 0x65 0x01 0x18 0x05 0x65>;
				phandle = <0x45>;
			};
		};

		uart4 {

			uart4m1-xfer {
				rockchip,pins = <0x01 0x14 0x04 0x65 0x01 0x15 0x04 0x65>;
				phandle = <0x46>;
			};
		};

		uart5 {

			uart5m0-xfer {
				rockchip,pins = <0x03 0x07 0x02 0x65 0x03 0x06 0x02 0x65>;
				phandle = <0x47>;
			};
		};

		gpio1-pc7 {

			gpio1-pc7 {
				rockchip,pins = <0x01 0x17 0x00 0x63>;
				phandle = <0x6f>;
			};
		};
	};

	rockchip-amp {
		compatible = "rockchip,amp";
		clocks = <0x02 0x3b 0x02 0x53 0x02 0x59 0x02 0x5f 0x02 0x42 0x02 0x123>;
		status = "okay";
	};

	adc-keys {
		compatible = "adc-keys";
		io-channels = <0x6c 0x00>;
		io-channel-names = "buttons";
		poll-interval = <0x64>;
		keyup-threshold-microvolt = <0x1b7740>;

		key_volumeup-key {
			label = "key_volumeup";
			linux,code = <0x73>;
			press-threshold-microvolt = <0x00>;
		};

		key_volumedown-key {
			label = "key_volumedown";
			linux,code = <0x72>;
			press-threshold-microvolt = <0x61d8d>;
		};
	};

	restart-poweroff {
		compatible = "restart-poweroff";
	};

	chosen {
		bootargs = "storagemedia=mtd androidboot.storagemedia=mtd androidboot.mode=normal  rootwait earlycon=uart8250,mmio32,0xff4c0000 console=ttyFIQ0 root=ubi0:rootfs snd_soc_core.prealloc_buffer_size_kbytes=16 coherent_pool=0 mtdparts=spi-nand0:256K(env),256K@256K(idblock),512K(uboot),4M(boot),30M(oem),6M(userdata),85M(rootfs) ubi.mtd=6 rootfstype=ubifs rk_dma_heap_cma=24M androidboot.fwver=uboot-06/26/2025";
	};

	acodec-sound {
		compatible = "simple-audio-card";
		simple-audio-card,name = "rv-acodec";
		simple-audio-card,format = "i2s";
		simple-audio-card,mclk-fs = <0x100>;

		simple-audio-card,cpu {
			sound-dai = <0x6d>;
		};

		simple-audio-card,codec {
			sound-dai = <0x6e>;
		};
	};

	vcc-1v8 {
		compatible = "regulator-fixed";
		regulator-name = "vcc_1v8";
		regulator-always-on;
		regulator-boot-on;
		regulator-min-microvolt = <0x1b7740>;
		regulator-max-microvolt = <0x1b7740>;
		phandle = <0x2d>;
	};

	vcc-3v3 {
		compatible = "regulator-fixed";
		regulator-name = "vcc_3v3";
		regulator-always-on;
		regulator-boot-on;
		regulator-min-microvolt = <0x325aa0>;
		regulator-max-microvolt = <0x325aa0>;
	};

	vdd-arm {
		compatible = "regulator-fixed";
		regulator-name = "vdd_arm";
		regulator-min-microvolt = <0xdbba0>;
		regulator-max-microvolt = <0xdbba0>;
		regulator-always-on;
		regulator-boot-on;
		phandle = <0x04>;
	};

	leds {
		compatible = "gpio-leds";

		work {
			gpios = <0x31 0x16 0x00>;
			linux,default-trigger = "activity";
			default-state = "on";
		};
	};

	dht11_sensor {
		compatible = "dht11";
		pinctrl-names = "default";
		pinctrl-0 = <0x6f>;

		dht11@1 {
			gpios = <0x36 0x17 0x00>;
			label = "dht11";
			linux,default-trigger = "humidity";
		};
	};
};
